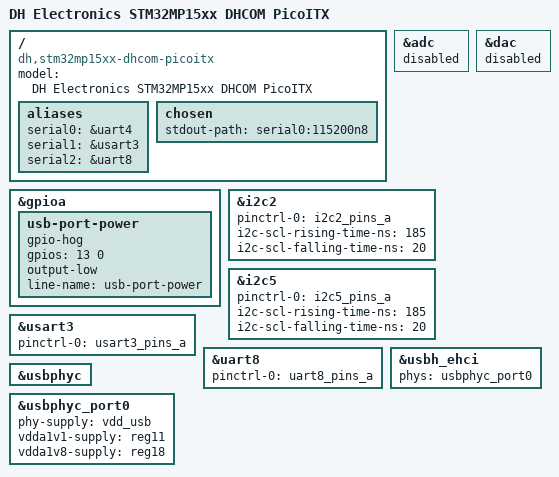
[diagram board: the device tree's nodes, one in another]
// SPDX-License-Identifier: GPL-2.0+ OR BSD-3-Clause
/*
 * Copyright (C) 2020 Marek Vasut <marex@denx.de>
 */

#include "stm32mp15xx-dhcom.dtsi"

/ {
	model = "DH Electronics STM32MP15xx DHCOM PicoITX";
	compatible = "dh,stm32mp15xx-dhcom-picoitx", "st,stm32mp1xx";

	aliases {
		serial0 = &uart4;
		serial1 = &usart3;
		serial2 = &uart8;
	};

	chosen {
		stdout-path = "serial0:115200n8";
	};
};

&adc {
	status = "disabled";
};

&dac {
	status = "disabled";
};

&gpioa {
	/*
	 * NOTE: The USB Port on the PicoITX needs a PWR_EN signal to enable
	 * port power. This signal should be handled by USB power sequencing
	 * in order to turn on port power when USB bus is powered up, but so
	 * far there is no such functionality.
	 */
	usb-port-power {
		gpio-hog;
		gpios = <13 0>;
		output-low;
		line-name = "usb-port-power";
	};
};

&i2c2 {	/* On board-to-board connector (optional) */
	pinctrl-names = "default";
	pinctrl-0 = <&i2c2_pins_a>;
	i2c-scl-rising-time-ns = <185>;
	i2c-scl-falling-time-ns = <20>;
	status = "okay";
	/* spare dmas for other usage */
	/delete-property/dmas;
	/delete-property/dma-names;
};

&i2c5 {	/* On board-to-board connector */
	pinctrl-names = "default";
	pinctrl-0 = <&i2c5_pins_a>;
	i2c-scl-rising-time-ns = <185>;
	i2c-scl-falling-time-ns = <20>;
	status = "okay";
	/* spare dmas for other usage */
	/delete-property/dmas;
	/delete-property/dma-names;
};

&usart3 {
	pinctrl-names = "default";
	pinctrl-0 = <&usart3_pins_a>;
	status = "okay";
};

&uart8 {
	pinctrl-names = "default";
	pinctrl-0 = <&uart8_pins_a>;
	status = "okay";
};

&usbh_ehci {
	phys = <&usbphyc_port0>;
	status = "okay";
};

&usbphyc {
	status = "okay";
};

&usbphyc_port0 {
	phy-supply = <&vdd_usb>;
	vdda1v1-supply = <&reg11>;
	vdda1v8-supply = <&reg18>;
};
